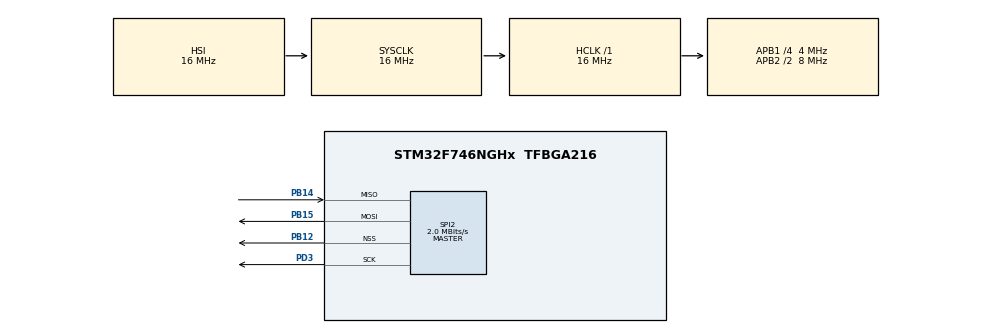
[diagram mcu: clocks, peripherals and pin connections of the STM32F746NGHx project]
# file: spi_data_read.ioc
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Mcu.Family=STM32F7
Mcu.Name=STM32F746NGHx
Mcu.Package=TFBGA216
NVIC.PriorityGroup=NVIC_PRIORITYGROUP_4
PB12.Mode=NSS_Signal_Hard_Output
PB12.Signal=SPI2_NSS
PB14.Mode=Full_Duplex_Master
PB14.Signal=SPI2_MISO
PB15.Mode=Full_Duplex_Master
PB15.Signal=SPI2_MOSI
PD3.Mode=Full_Duplex_Master
PD3.Signal=SPI2_SCK
PH0/OSC_IN.Mode=HSE-External-Oscillator
PH0/OSC_IN.Signal=RCC_OSC_IN
PH1/OSC_OUT.Mode=HSE-External-Oscillator
PH1/OSC_OUT.Signal=RCC_OSC_OUT
ProjectManager.HeapSize=0x200
ProjectManager.StackSize=0x400
ProjectManager.TargetToolchain=STM32CubeIDE
RCC.AHBFreq_Value=16000000
RCC.APB1CLKDivider=RCC_HCLK_DIV4
RCC.APB1Freq_Value=4000000
RCC.APB1TimFreq_Value=8000000
RCC.APB2CLKDivider=RCC_HCLK_DIV2
RCC.APB2Freq_Value=8000000
RCC.APB2TimFreq_Value=16000000
RCC.CortexFreq_Value=16000000
RCC.HCLKFreq_Value=16000000
RCC.HSE_VALUE=25000000
RCC.HSI_VALUE=16000000
RCC.LSE_VALUE=32768
RCC.PLL48CLockSelection=RCC_CLK48SOURCE_PLLSAIP
RCC.PLLI2SN=100
RCC.PLLM=25
RCC.PLLN=128
RCC.PLLQ=9
RCC.PLLSAIN=384
RCC.PLLSAIP=RCC_PLLSAIP_DIV8
RCC.PLLSAIR=5
RCC.PLLSAIRDiv=RCC_PLLSAIDIVR_8
RCC.PLLSourceVirtual=RCC_PLLSOURCE_HSE
RCC.SDMMCClockSelection=RCC_SDMMC1CLKSOURCE_CLK48
RCC.SYSCLKFreq_VALUE=16000000
RCC.USBFreq_Value=48000000
RCC.VCOOutputFreq_Value=128000000
SPI2.BaudRatePrescaler=SPI_BAUDRATEPRESCALER_2
SPI2.CLKPhase=SPI_PHASE_2EDGE
SPI2.CLKPolarity=SPI_POLARITY_HIGH
SPI2.CRCCalculation=SPI_CRCCALCULATION_DISABLE
SPI2.CalculateBaudRate=2.0 MBits/s
SPI2.DataSize=SPI_DATASIZE_8BIT
SPI2.Direction=SPI_DIRECTION_2LINES
SPI2.Mode=SPI_MODE_MASTER
SPI2.VirtualNSS=VM_NSSHARD
SPI2.VirtualType=VM_MASTER
board=STM32F746G-DISCO

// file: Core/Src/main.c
/* USER CODE BEGIN Header */
/**
  ******************************************************************************
  * @file           : main.c
  * @brief          : Main program body
  ******************************************************************************
  * @attention
  *
  * Copyright (c) 2025 STMicroelectronics.
  * All rights reserved.
  *
  * This software is licensed under terms that can be found in the LICENSE file
  * in the root directory of this software component.
  * If no LICENSE file comes with this software, it is provided AS-IS.
  *
  ******************************************************************************
  */
/* USER CODE END Header */
#include "main.h"

SPI_HandleTypeDef hspi2;

/* USER CODE BEGIN PV */
uint16_t read_value = 0;
uint16_t debug_buffer = 0;

uint8_t target_register=0x91;  //  R|0|0|1|0|0|0|1|||||||
//0x1900---- 0x19__
//ox9900
/* USER CODE END PV */

void SystemClock_Config(void);
static void MX_GPIO_Init(void);
static void MX_SPI2_Init(void);
/* USER CODE BEGIN PFP */
void AD7779_ReadRegister(uint8_t reg);
/* USER CODE END PFP */

int main(void)
{

  /* MCU Configuration--------------------------------------------------------*/

  /* Reset of all peripherals, Initializes the Flash interface and the Systick. */
  HAL_Init();

  /* Configure the system clock */
  SystemClock_Config();

  /* Initialize all configured peripherals */
  MX_GPIO_Init();
  MX_SPI2_Init();
  /* USER CODE BEGIN 2 */
  AD7779_ReadRegister(target_register);
  read_value = debug_buffer;
  /* USER CODE END 2 */

  /* Infinite loop */
  while (1)
  {

  }
}

void SystemClock_Config(void)
{
  RCC_OscInitTypeDef RCC_OscInitStruct = {0};
  RCC_ClkInitTypeDef RCC_ClkInitStruct = {0};

  /** Configure the main internal regulator output voltage
  */
  __HAL_RCC_PWR_CLK_ENABLE();
  __HAL_PWR_VOLTAGESCALING_CONFIG(PWR_REGULATOR_VOLTAGE_SCALE3);

  /** Initializes the RCC Oscillators according to the specified parameters
  * in the RCC_OscInitTypeDef structure.
  */
  RCC_OscInitStruct.OscillatorType = RCC_OSCILLATORTYPE_HSI;
  RCC_OscInitStruct.HSIState = RCC_HSI_ON;
  RCC_OscInitStruct.HSICalibrationValue = RCC_HSICALIBRATION_DEFAULT;
  RCC_OscInitStruct.PLL.PLLState = RCC_PLL_NONE;
  if (HAL_RCC_OscConfig(&RCC_OscInitStruct) != HAL_OK)
  {
    Error_Handler();
  }

  /** Initializes the CPU, AHB and APB buses clocks
  */
  RCC_ClkInitStruct.ClockType = RCC_CLOCKTYPE_HCLK|RCC_CLOCKTYPE_SYSCLK
                              |RCC_CLOCKTYPE_PCLK1|RCC_CLOCKTYPE_PCLK2;
  RCC_ClkInitStruct.SYSCLKSource = RCC_SYSCLKSOURCE_HSI;
  RCC_ClkInitStruct.AHBCLKDivider = RCC_SYSCLK_DIV1;
  RCC_ClkInitStruct.APB1CLKDivider = RCC_HCLK_DIV4;
  RCC_ClkInitStruct.APB2CLKDivider = RCC_HCLK_DIV2;

  if (HAL_RCC_ClockConfig(&RCC_ClkInitStruct, FLASH_LATENCY_0) != HAL_OK)
  {
    Error_Handler();
  }
}

static void MX_SPI2_Init(void)
{

  /* SPI2 parameter configuration*/
  hspi2.Instance = SPI2;
  hspi2.Init.Mode = SPI_MODE_MASTER;
  hspi2.Init.Direction = SPI_DIRECTION_2LINES;
  hspi2.Init.DataSize = SPI_DATASIZE_8BIT;
  hspi2.Init.CLKPolarity = SPI_POLARITY_HIGH;
  hspi2.Init.CLKPhase = SPI_PHASE_2EDGE;
  hspi2.Init.NSS = SPI_NSS_HARD_OUTPUT;
  hspi2.Init.BaudRatePrescaler = SPI_BAUDRATEPRESCALER_2;
  hspi2.Init.FirstBit = SPI_FIRSTBIT_MSB;
  hspi2.Init.TIMode = SPI_TIMODE_DISABLE;
  hspi2.Init.CRCCalculation = SPI_CRCCALCULATION_DISABLE;
  hspi2.Init.CRCPolynomial = 7;
  hspi2.Init.CRCLength = SPI_CRC_LENGTH_DATASIZE;
  hspi2.Init.NSSPMode = SPI_NSS_PULSE_DISABLE;
  if (HAL_SPI_Init(&hspi2) != HAL_OK)
  {
    Error_Handler();
  }

}

static void MX_GPIO_Init(void)
{

  /* GPIO Ports Clock Enable */
  __HAL_RCC_GPIOD_CLK_ENABLE();
  __HAL_RCC_GPIOH_CLK_ENABLE();
  __HAL_RCC_GPIOB_CLK_ENABLE();

}

/* USER CODE BEGIN 4 */
void AD7779_ReadRegister(uint8_t reg)
{
    uint8_t tx_buf[2];
    uint8_t rx_buf[2];

    tx_buf[0] = reg;   // reg = 0x99 (already has read bit set)
    tx_buf[1] = 0x00;  // dummy byte to receive data

    // Full-duplex SPI: transmit 2 bytes, receive 2 bytes
    HAL_SPI_TransmitReceive(&hspi2, tx_buf, rx_buf, 2, HAL_MAX_DELAY);

    // Register data is returned in second byte
    debug_buffer = rx_buf[1];
	   /* uint16_t tx = reg;     // This should be 0x91XX format for a read operation
	    uint16_t dummy = 0x0000;
	    uint16_t rx = 0;

	    HAL_GPIO_WritePin(GPIOB, GPIO_PIN_12, GPIO_PIN_RESET); // Pull CS low (adjust pin/port as needed)

	    // Send the register address with read bit set
	    if (HAL_SPI_Transmit(&hspi2, (uint8_t *)&tx, 1, HAL_MAX_DELAY) != HAL_OK)
	    {
	        Error_Handler();
	    }

	    // Send dummy data to read the response
	    if (HAL_SPI_TransmitReceive(&hspi2, (uint8_t *)&dummy, (uint8_t *)&rx, 1, HAL_MAX_DELAY) != HAL_OK)
	    {
	        Error_Handler();
	    }

	    HAL_GPIO_WritePin(GPIOB, GPIO_PIN_12, GPIO_PIN_SET); // Pull CS high

	    debug_buffer = rx;*/

}
/*
 * void AD7779_ReadRegister(uint8_t reg)
{
    uint8_t tx_buf[3];
    uint8_t rx_buf[3];

    // Construct read command: first byte is 0x40 | (reg & 0x3F)
    tx_buf[0] = 0x40 | (reg & 0x3F);  // Read command
    tx_buf[1] = 0x00;                 // Dummy byte
    tx_buf[2] = 0x00;                 // Placeholder for read data

    // Perform full 3-byte transaction
    HAL_SPI_TransmitReceive(&hspi2, tx_buf, rx_buf, 3, HAL_MAX_DELAY);

    // Store the received register data
    debug_buffer = rx_buf[2];
}
 * */
/* USER CODE END 4 */

void Error_Handler(void)
{
  __disable_irq();
  while (1)
  {
  }
}
